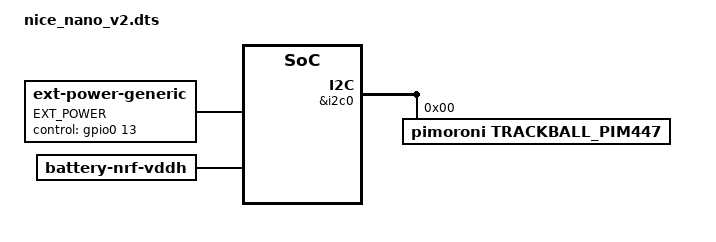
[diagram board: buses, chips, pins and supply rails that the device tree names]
/*
 * Copyright (c) 2021 The ZMK Contributors
 *
 * SPDX-License-Identifier: MIT
 */

/dts-v1/;
#include "nice_nano.dtsi"

/ {
    ext-power {
        compatible = "zmk,ext-power-generic";
        label = "EXT_POWER";
        control-gpios = <&gpio0 13 GPIO_ACTIVE_HIGH>;
        init-delay-ms = <10>;
    };

    vbatt {
        compatible = "zmk,battery-nrf-vddh";
        label = "BATTERY";
    };

    // I2C 장치 추가
    &i2c0 {
        trackball_pim447@0 {
            compatible = "pimoroni,trackball_pim447"; // 드라이버와 일치해야 함
            reg = <0x0>;            // I2C 주소 (필요에 따라 수정)
            move-factor = <1>;      // 포인터 이동 계수
            button = <3>;           // 버튼 설정
            scroll-divisor = <10>;  // 스크롤 분배자
            mode = <0>;             // 트랙볼 모드
        };
    };
};
